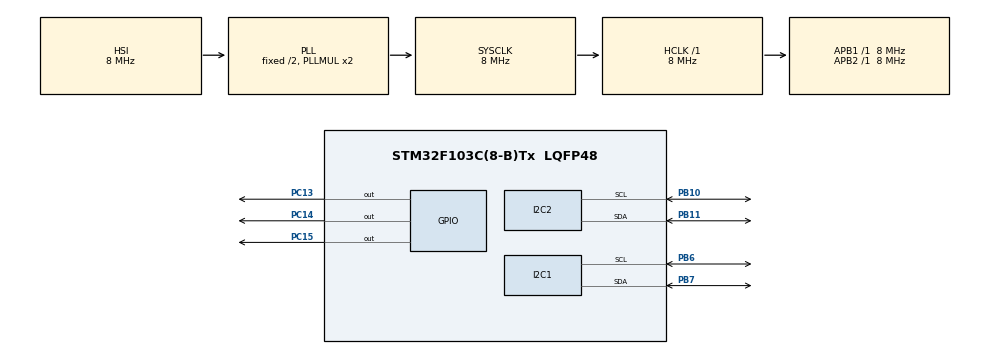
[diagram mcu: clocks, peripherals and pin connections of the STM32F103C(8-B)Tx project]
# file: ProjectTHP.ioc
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I2C1.I2C_Mode=I2C_Fast
I2C2.I2C_Mode=I2C_Fast
Mcu.Family=STM32F1
Mcu.Name=STM32F103C(8-B)Tx
Mcu.Package=LQFP48
NVIC.PriorityGroup=NVIC_PRIORITYGROUP_4
PA13.Mode=Serial_Wire
PA13.Signal=SYS_JTMS-SWDIO
PA14.Mode=Serial_Wire
PA14.Signal=SYS_JTCK-SWCLK
PB10.Mode=I2C
PB10.Signal=I2C2_SCL
PB11.Mode=I2C
PB11.Signal=I2C2_SDA
PB6.Mode=I2C
PB6.Signal=I2C1_SCL
PB7.Mode=I2C
PB7.Signal=I2C1_SDA
PC13-TAMPER-RTC.Signal=GPIO_Output
PC14-OSC32_IN.Signal=GPIO_Output
PC15-OSC32_OUT.Signal=GPIO_Output
ProjectManager.HeapSize=0x200
ProjectManager.StackSize=0x400
ProjectManager.TargetToolchain=MDK-ARM V5.27
RCC.AHBFreq_Value=8000000
RCC.APB1Freq_Value=8000000
RCC.APB1TimFreq_Value=8000000
RCC.APB2Freq_Value=8000000
RCC.APB2TimFreq_Value=8000000
RCC.HCLKFreq_Value=8000000
RCC.SYSCLKFreq_VALUE=8000000
RCC.SYSCLKSource=RCC_SYSCLKSOURCE_PLLCLK
RCC.USBFreq_Value=8000000
board=custom

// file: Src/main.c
/* USER CODE BEGIN Header */
/**
  ******************************************************************************
  * @file           : main.c
  * @brief          : Main program body
  ******************************************************************************
  * @attention
  *
  * <h2><center>&copy; Copyright (c) 2019 STMicroelectronics.
  * All rights reserved.</center></h2>
  *
  * This software component is licensed by ST under BSD 3-Clause license,
  * the "License"; You may not use this file except in compliance with the
  * License. You may obtain a copy of the License at:
  *                        opensource.org/licenses/BSD-3-Clause
  *
  ******************************************************************************
  */
/* USER CODE END Header */

#include <stdio.h>
#include <string.h>
#include <math.h>
#include "main.h"
#include "i2c.h"
#include "gpio.h"
#include "bmp180.h"
#include "htu21.h"
#include "ssd1306.h"
#include "fonts.h"
#include "ind.h"

void SystemClock_Config(void);

int main(void)
{
  /* USER CODE BEGIN 1 */

	htuData htuValues;
	bmpData bmpValues;

	char htuHum = NULL;
	char avgTemp = NULL;
	float temp2Display = 0.0;

  /* USER CODE END 1 */

  /* MCU Configuration--------------------------------------------------------*/

  /* Reset of all peripherals, Initializes the Flash interface and the Systick. */
  HAL_Init();

  /* Configure the system clock */
  SystemClock_Config();

  /* Initialize all configured peripherals */
  MX_GPIO_Init();
  MX_I2C1_Init();
  MX_I2C2_Init();
  /* USER CODE BEGIN 2 */

	SSD1306_Init();
	SSD1306_Fill(0);
	SSD1306_UpdateScreen();
	SSD1306_GotoXY(10, 10);

	init_bmp(&bmpValues);
	reset_indication();
  /* USER CODE END 2 */

  /* Infinite loop */
  /* USER CODE BEGIN WHILE */
  while (1)
  {
			clean_up_htu(&htuValues);
			clean_up_bmp(&bmpValues);
			read_htu_temp(&htuValues);
			read_htu_hum(&htuValues);

			read_uncomp_temp(&bmpValues);
			read_comp_temp(&bmpValues);

			upd_temp_2_display(
				bmpValues.compData.temp,
				htuValues.temp,
				&temp2Display
			);

			SSD1306_Fill(0);

			SSD1306_GotoXY(15, 15);
			sprintf(&avgTemp, "Temp: %iC", (int)temp2Display);
			SSD1306_Puts(&avgTemp, &Font_11x18, 1);

			SSD1306_GotoXY(15, 40);
			sprintf(&htuHum, "Humi: %i%%", (int)htuValues.hum);
			SSD1306_Puts(&htuHum, &Font_11x18, 1);

			SSD1306_UpdateScreen();

			indicate_condition(temp2Display);
			HAL_Delay(5000);
			reset_indication();
			HAL_Delay(5000);
  }
}

void SystemClock_Config(void)
{
  RCC_OscInitTypeDef RCC_OscInitStruct = {0};
  RCC_ClkInitTypeDef RCC_ClkInitStruct = {0};

  /** Initializes the CPU, AHB and APB busses clocks
  */
  RCC_OscInitStruct.OscillatorType = RCC_OSCILLATORTYPE_HSI;
  RCC_OscInitStruct.HSIState = RCC_HSI_ON;
  RCC_OscInitStruct.HSICalibrationValue = RCC_HSICALIBRATION_DEFAULT;
  RCC_OscInitStruct.PLL.PLLState = RCC_PLL_ON;
  RCC_OscInitStruct.PLL.PLLSource = RCC_PLLSOURCE_HSI_DIV2;
  RCC_OscInitStruct.PLL.PLLMUL = RCC_PLL_MUL2;
  if (HAL_RCC_OscConfig(&RCC_OscInitStruct) != HAL_OK)
  {
    Error_Handler();
  }
  /** Initializes the CPU, AHB and APB busses clocks
  */
  RCC_ClkInitStruct.ClockType = RCC_CLOCKTYPE_HCLK|RCC_CLOCKTYPE_SYSCLK
                              |RCC_CLOCKTYPE_PCLK1|RCC_CLOCKTYPE_PCLK2;
  RCC_ClkInitStruct.SYSCLKSource = RCC_SYSCLKSOURCE_PLLCLK;
  RCC_ClkInitStruct.AHBCLKDivider = RCC_SYSCLK_DIV1;
  RCC_ClkInitStruct.APB1CLKDivider = RCC_HCLK_DIV1;
  RCC_ClkInitStruct.APB2CLKDivider = RCC_HCLK_DIV1;

  if (HAL_RCC_ClockConfig(&RCC_ClkInitStruct, FLASH_LATENCY_0) != HAL_OK)
  {
    Error_Handler();
  }
}

void Error_Handler(void)
{
}

/************************ (C) COPYRIGHT STMicroelectronics *****END OF FILE****/
